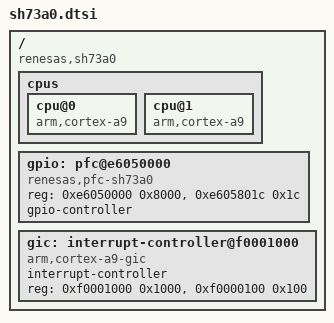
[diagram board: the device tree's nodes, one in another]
/*
 * Device Tree Source for the SH73A0 SoC
 *
 * Copyright (C) 2012 Renesas Solutions Corp.
 *
 * This file is licensed under the terms of the GNU General Public License
 * version 2.  This program is licensed "as is" without any warranty of any
 * kind, whether express or implied.
 */

/include/ "skeleton.dtsi"

/ {
	compatible = "renesas,sh73a0";

	cpus {
		cpu@0 {
			compatible = "arm,cortex-a9";
		};
		cpu@1 {
			compatible = "arm,cortex-a9";
		};
	};

	gpio: pfc@e6050000 {
		compatible = "renesas,pfc-sh73a0";
		reg = <0xe6050000 0x8000>,
		      <0xe605801c 0x1c>;
		gpio-controller;
		#gpio-cells = <2>;
	};

	gic: interrupt-controller@f0001000 {
		compatible = "arm,cortex-a9-gic";
		#interrupt-cells = <3>;
		#address-cells = <1>;
		interrupt-controller;
		reg = <0xf0001000 0x1000>,
		      <0xf0000100 0x100>;
	};
};
